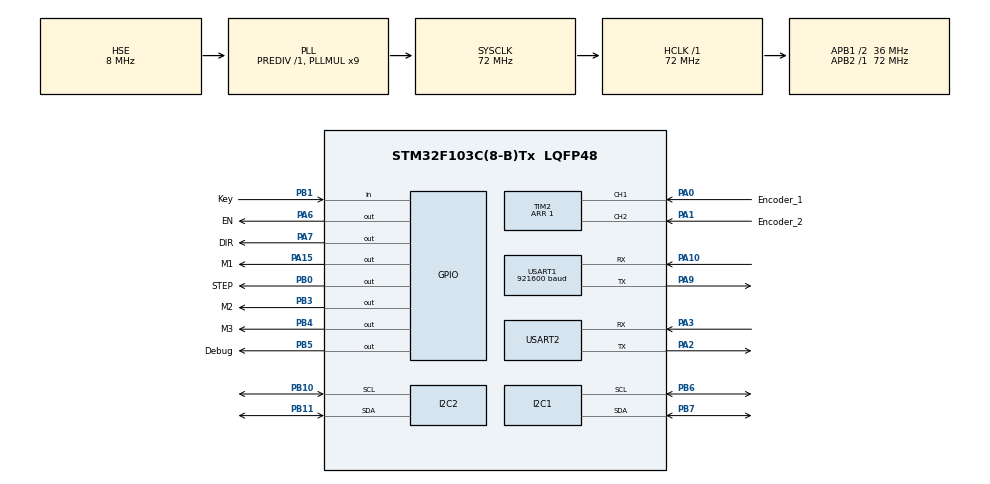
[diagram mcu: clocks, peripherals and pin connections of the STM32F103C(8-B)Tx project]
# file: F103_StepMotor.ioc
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Dma.Request0=USART1_TX
Dma.USART1_TX.0.Direction=DMA_MEMORY_TO_PERIPH
Dma.USART1_TX.0.Instance=DMA1_Channel4
Dma.USART1_TX.0.MemDataAlignment=DMA_MDATAALIGN_BYTE
Dma.USART1_TX.0.MemInc=DMA_MINC_ENABLE
Dma.USART1_TX.0.Mode=DMA_NORMAL
Dma.USART1_TX.0.PeriphDataAlignment=DMA_PDATAALIGN_BYTE
Dma.USART1_TX.0.PeriphInc=DMA_PINC_DISABLE
Dma.USART1_TX.0.Priority=DMA_PRIORITY_LOW
I2C1.I2C_Mode=I2C_Fast
I2C2.I2C_Mode=I2C_Standard
Mcu.Family=STM32F1
Mcu.Name=STM32F103C(8-B)Tx
Mcu.Package=LQFP48
NVIC.DMA1_Channel4_IRQn=true\:0\:0\:false\:false\:true\:false\:true\:true
NVIC.PriorityGroup=NVIC_PRIORITYGROUP_4
NVIC.TIM4_IRQn=true\:0\:0\:false\:false\:false\:true\:true\:true
NVIC.USART1_IRQn=true\:0\:0\:false\:false\:true\:true\:true\:true
PA0-WKUP.GPIO_Label=Encoder_1
PA0-WKUP.Signal=S_TIM2_CH1_ETR
PA1.GPIO_Label=Encoder_2
PA1.Signal=S_TIM2_CH2
PA10.Mode=Asynchronous
PA10.Signal=USART1_RX
PA13.Mode=Serial_Wire
PA13.Signal=SYS_JTMS-SWDIO
PA14.Mode=Serial_Wire
PA14.Signal=SYS_JTCK-SWCLK
PA15.GPIO_Label=M1
PA15.Signal=GPIO_Output
PA2.Mode=Asynchronous
PA2.Signal=USART2_TX
PA3.Mode=Asynchronous
PA3.Signal=USART2_RX
PA6.GPIO_Label=EN
PA6.GPIO_Speed=GPIO_SPEED_FREQ_HIGH
PA6.Signal=GPIO_Output
PA7.GPIO_Label=DIR
PA7.GPIO_Speed=GPIO_SPEED_FREQ_HIGH
PA7.Signal=GPIO_Output
PA9.Mode=Asynchronous
PA9.Signal=USART1_TX
PB0.GPIO_Label=STEP
PB0.GPIO_Speed=GPIO_SPEED_FREQ_HIGH
PB0.Signal=GPIO_Output
PB1.GPIO_Label=Key
PB1.GPIO_PuPd=GPIO_PULLUP
PB1.Signal=GPIO_Input
PB10.Mode=I2C
PB10.Signal=I2C2_SCL
PB11.Mode=I2C
PB11.Signal=I2C2_SDA
PB3.GPIO_Label=M2
PB3.Signal=GPIO_Output
PB4.GPIO_Label=M3
PB4.Signal=GPIO_Output
PB5.GPIO_Label=Debug
PB5.Signal=GPIO_Output
PB6.Mode=I2C
PB6.Signal=I2C1_SCL
PB7.Mode=I2C
PB7.Signal=I2C1_SDA
PD0-OSC_IN.Mode=HSE-External-Oscillator
PD0-OSC_IN.Signal=RCC_OSC_IN
PD1-OSC_OUT.Mode=HSE-External-Oscillator
PD1-OSC_OUT.Signal=RCC_OSC_OUT
ProjectManager.HeapSize=0x000
ProjectManager.StackSize=0x800
ProjectManager.TargetToolchain=STM32CubeIDE
RCC.AHBFreq_Value=72000000
RCC.APB1CLKDivider=RCC_HCLK_DIV2
RCC.APB1Freq_Value=36000000
RCC.APB1TimFreq_Value=72000000
RCC.APB2Freq_Value=72000000
RCC.APB2TimFreq_Value=72000000
RCC.HCLKFreq_Value=72000000
RCC.PLLMUL=RCC_PLL_MUL9
RCC.PLLSourceVirtual=RCC_PLLSOURCE_HSE
RCC.SYSCLKFreq_VALUE=72000000
RCC.SYSCLKSource=RCC_SYSCLKSOURCE_PLLCLK
RCC.USBFreq_Value=72000000
SH.S_TIM2_CH1_ETR.0=TIM2_CH1,Encoder_Interface
SH.S_TIM2_CH2.0=TIM2_CH2,Encoder_Interface
TIM2.IC1Filter=15
TIM2.IC1Prescaler=TIM_ICPSC_DIV8
TIM2.IC2Filter=15
TIM2.IC2Prescaler=TIM_ICPSC_DIV8
TIM2.Period=1
TIM4.Period=65535
TIM4.Prescaler=71
USART1.BaudRate=921600
USART1.VirtualMode=VM_ASYNC
USART2.VirtualMode=VM_ASYNC
VP_TIM4_VS_ClockSourceINT.Mode=Internal
board=custom

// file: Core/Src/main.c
/* USER CODE BEGIN Header */
/**
  ******************************************************************************
  * @file           : main.c
  * @brief          : Main program body
  ******************************************************************************
  * @attention
  *
  * Copyright (c) 2023 STMicroelectronics.
  * All rights reserved.
  *
  * This software is licensed under terms that can be found in the LICENSE file
  * in the root directory of this software component.
  * If no LICENSE file comes with this software, it is provided AS-IS.
  *
  ******************************************************************************
  */
/* USER CODE END Header */
#include "main.h"
#include "dma.h"
#include "i2c.h"
#include "tim.h"
#include "usart.h"
#include "gpio.h"

/* USER CODE BEGIN Includes */
#include "dwt.h"
/* USER CODE END Includes */

/* USER CODE BEGIN PD */
extern void setup(void);
/* USER CODE END PD */

void SystemClock_Config(void);

int main(void)
{

  /* MCU Configuration--------------------------------------------------------*/

  /* Reset of all peripherals, Initializes the Flash interface and the Systick. */
  HAL_Init();

  /* Configure the system clock */
  SystemClock_Config();

  /* Initialize all configured peripherals */
  MX_GPIO_Init();
  MX_DMA_Init();
  MX_I2C1_Init();
  MX_I2C2_Init();
  MX_TIM2_Init();
  MX_USART1_UART_Init();
  MX_USART2_UART_Init();
  MX_TIM4_Init();
  /* USER CODE BEGIN 2 */
  HAL_TIM_Base_Start_IT(&htim4); //Запуск таймера микросекунд
  DWT_Init();
  //I2C нужно ставить 800000

  HAL_Delay(100);
  setup();

     //xTraceEnable(TRC_START);
  /* USER CODE END 2 */

  /* Infinite loop */
  while (1)
  {

  }
}

void SystemClock_Config(void)
{
  RCC_OscInitTypeDef RCC_OscInitStruct = {0};
  RCC_ClkInitTypeDef RCC_ClkInitStruct = {0};

  /** Initializes the RCC Oscillators according to the specified parameters
  * in the RCC_OscInitTypeDef structure.
  */
  RCC_OscInitStruct.OscillatorType = RCC_OSCILLATORTYPE_HSE;
  RCC_OscInitStruct.HSEState = RCC_HSE_ON;
  RCC_OscInitStruct.HSEPredivValue = RCC_HSE_PREDIV_DIV1;
  RCC_OscInitStruct.HSIState = RCC_HSI_ON;
  RCC_OscInitStruct.PLL.PLLState = RCC_PLL_ON;
  RCC_OscInitStruct.PLL.PLLSource = RCC_PLLSOURCE_HSE;
  RCC_OscInitStruct.PLL.PLLMUL = RCC_PLL_MUL9;
  if (HAL_RCC_OscConfig(&RCC_OscInitStruct) != HAL_OK)
  {
    Error_Handler();
  }

  /** Initializes the CPU, AHB and APB buses clocks
  */
  RCC_ClkInitStruct.ClockType = RCC_CLOCKTYPE_HCLK|RCC_CLOCKTYPE_SYSCLK
                              |RCC_CLOCKTYPE_PCLK1|RCC_CLOCKTYPE_PCLK2;
  RCC_ClkInitStruct.SYSCLKSource = RCC_SYSCLKSOURCE_PLLCLK;
  RCC_ClkInitStruct.AHBCLKDivider = RCC_SYSCLK_DIV1;
  RCC_ClkInitStruct.APB1CLKDivider = RCC_HCLK_DIV2;
  RCC_ClkInitStruct.APB2CLKDivider = RCC_HCLK_DIV1;

  if (HAL_RCC_ClockConfig(&RCC_ClkInitStruct, FLASH_LATENCY_2) != HAL_OK)
  {
    Error_Handler();
  }
}

void Error_Handler(void)
{
  __disable_irq();
  while (1)
  {
  }
}
